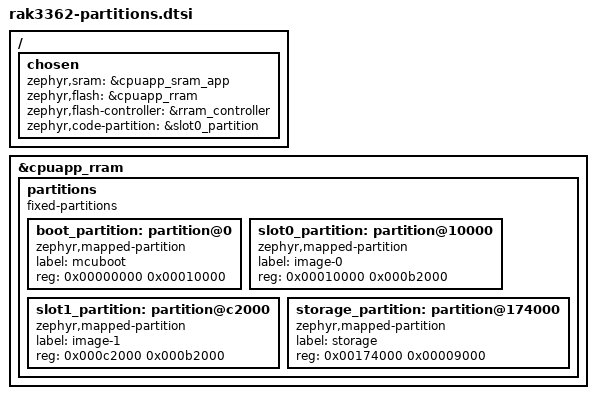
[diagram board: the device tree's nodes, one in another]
/* SPDX-FileCopyrightText: Copyright (c) 2026 RAKwireless */
/* SPDX-License-Identifier: Apache-2.0 */
/*
 * rak3362 flash map (nRF54L15, 1428 KB RRAM for the application core).
 * MCUboot boots slot0. Slot1 is the FUOTA / overwrite image.
 *
 * 64K boot + 712K slot0 + 712K slot1 + 36K storage.
 */

/ {
	chosen {
		zephyr,sram = &cpuapp_sram_app;
		zephyr,flash = &cpuapp_rram;
		zephyr,flash-controller = &rram_controller;
		zephyr,code-partition = &slot0_partition;
	};
};

&cpuapp_rram {
	partitions {
		compatible = "fixed-partitions";
		ranges;
		#address-cells = <1>;
		#size-cells = <1>;

		boot_partition: partition@0 {
			compatible = "zephyr,mapped-partition";
			label = "mcuboot";
			reg = <0x00000000 0x00010000>;
		};

		slot0_partition: partition@10000 {
			compatible = "zephyr,mapped-partition";
			label = "image-0";
			reg = <0x00010000 0x000b2000>;
		};

		slot1_partition: partition@c2000 {
			compatible = "zephyr,mapped-partition";
			label = "image-1";
			reg = <0x000c2000 0x000b2000>;
		};

		storage_partition: partition@174000 {
			compatible = "zephyr,mapped-partition";
			label = "storage";
			reg = <0x00174000 0x00009000>;
		};
	};
};
